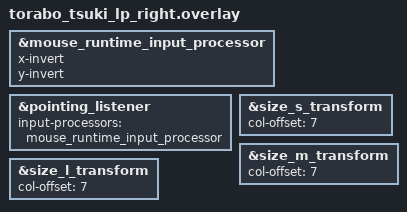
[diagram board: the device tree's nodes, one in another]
#define TORABO_TSUKI_LP_RIGHT 1
#define TORABO_TSUKI_LP_MATRIX_COL_OFFSET 7

#include "torabo_tsuki_lp.dtsi"
#include <input/processors.dtsi>
#include <input/processors/runtime-input-processor.dtsi>
#include <zephyr/dt-bindings/input/input-event-codes.h>

&mouse_runtime_input_processor {
    /* Preserve the current physical trackball direction. */
    x-invert;
    y-invert;
};

&pointing_listener {
    input-processors = <&mouse_runtime_input_processor>;
};

&size_s_transform {
    col-offset = <7>;
};

&size_m_transform {
    col-offset = <7>;
};

&size_l_transform {
    col-offset = <7>;
};
